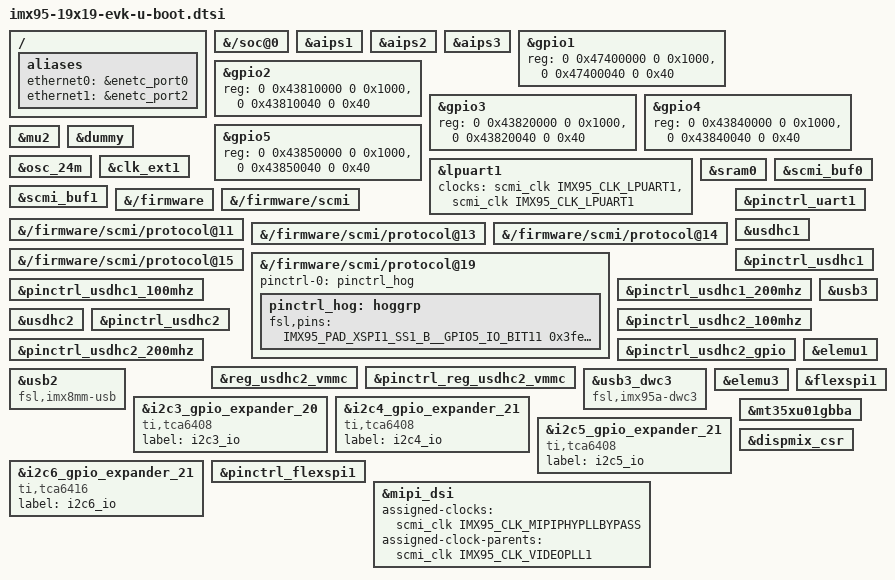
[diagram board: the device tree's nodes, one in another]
// SPDX-License-Identifier: GPL-2.0+
/*
 * Copyright 2023 NXP
 */

/ {
	aliases {
		ethernet0 = &enetc_port0;
		ethernet1 = &enetc_port2;
	};
};

&{/soc@0} {
	bootph-all;
	bootph-pre-ram;
};

&aips1 {
	bootph-all;
	bootph-pre-ram;
};

&aips2 {
	bootph-all;
	bootph-pre-ram;
};

&aips3 {
	bootph-pre-ram;
};

&gpio1 {
	reg = <0 0x47400000 0 0x1000>, <0 0x47400040 0 0x40>;
};

&gpio2 {
	reg = <0 0x43810000 0 0x1000>, <0 0x43810040 0 0x40>;
	bootph-pre-ram;
};

&gpio3 {
	reg = <0 0x43820000 0 0x1000>, <0 0x43820040 0 0x40>;
	bootph-pre-ram;
};

&gpio4 {
	reg = <0 0x43840000 0 0x1000>, <0 0x43840040 0 0x40>;
	bootph-pre-ram;
};

&gpio5 {
	reg = <0 0x43850000 0 0x1000>, <0 0x43850040 0 0x40>;
	bootph-pre-ram;
};

&lpuart1 {
	clocks = <&scmi_clk IMX95_CLK_LPUART1>, <&scmi_clk IMX95_CLK_LPUART1>;
	clock-names = "ipg", "per";
	bootph-pre-ram;
};

&mu2 {
	bootph-all;
	bootph-pre-ram;
};

&dummy {
	bootph-all;
	bootph-pre-ram;
};

&osc_24m {
	bootph-all;
	bootph-pre-ram;
};

&clk_ext1 {
	bootph-all;
	bootph-pre-ram;
};

&sram0 {
	bootph-all;
	bootph-pre-ram;
};

&scmi_buf0 {
	bootph-all;
	bootph-pre-ram;
};

&scmi_buf1 {
	bootph-all;
	bootph-pre-ram;
};

&{/firmware} {
	bootph-all;
        bootph-pre-ram;
};

&{/firmware/scmi} {
	bootph-all;
        bootph-pre-ram;
};

&{/firmware/scmi/protocol@11} {
	bootph-all;
        bootph-pre-ram;
};

&{/firmware/scmi/protocol@13} {
	bootph-all;
        bootph-pre-ram;
};

&{/firmware/scmi/protocol@14} {
	bootph-all;
        bootph-pre-ram;
};

&{/firmware/scmi/protocol@15} {
	bootph-all;
};

&{/firmware/scmi/protocol@19} {
	bootph-all;
	bootph-pre-ram;

	pinctrl-names = "default";
	pinctrl-0 = <&pinctrl_hog>;

	pinctrl_hog: hoggrp {
		bootph-pre-ram;

		fsl,pins = <
			IMX95_PAD_XSPI1_SS1_B__GPIO5_IO_BIT11			0x3fe
			IMX95_PAD_GPIO_IO12__TPM3_CH2           0x51e
			IMX95_PAD_CCM_CLKO1__GPIO3_IO_BIT26			0x3fe
			IMX95_PAD_CCM_CLKO2__GPIO3_IO_BIT27			0x3fe
		>;
	};
};

&pinctrl_uart1 {
	bootph-pre-ram;
};

&usdhc1 {
	bootph-pre-ram;
};

&pinctrl_usdhc1 {
	bootph-pre-ram;
};

&pinctrl_usdhc1_100mhz {
	bootph-pre-ram;
};

&pinctrl_usdhc1_200mhz {
	bootph-pre-ram;
};

&usdhc2 {
	bootph-pre-ram;
};

&pinctrl_usdhc2 {
	bootph-pre-ram;
};

&pinctrl_usdhc2_100mhz {
	bootph-pre-ram;
};

&pinctrl_usdhc2_200mhz {
	bootph-pre-ram;
};

&pinctrl_usdhc2_gpio {
	bootph-pre-ram;
};

&reg_usdhc2_vmmc {
	bootph-pre-ram;
};

&pinctrl_reg_usdhc2_vmmc {
	bootph-pre-ram;
};

&usb2 {
	compatible = "fsl,imx8mm-usb", "fsl,imx7d-usb";
	/delete-property/power-domains;
};

&usb3 {
	/delete-property/power-domains;
};

&usb3_dwc3 {
	compatible = "fsl,imx95a-dwc3", "fsl,imx8mq-dwc3", "snps,dwc3";
};

&elemu1 {
	status = "okay";
	bootph-all;
	bootph-pre-ram;
};

&elemu3 {
	status = "okay";
	bootph-all;
	bootph-pre-ram;
};

&i2c3_gpio_expander_20 {
	compatible = "ti,tca6408";
	label = "i2c3_io";
};

&i2c4_gpio_expander_21 {
	compatible = "ti,tca6408";
	label = "i2c4_io";
};

&i2c5_gpio_expander_21 {
	compatible = "ti,tca6408";
	label = "i2c5_io";
};

&i2c6_gpio_expander_21 {
	compatible = "ti,tca6416";
	label = "i2c6_io";
};

&flexspi1 {
	bootph-pre-ram;
};

&mt35xu01gbba {
	bootph-pre-ram;
};

&pinctrl_flexspi1 {
	bootph-pre-ram;
};

&dispmix_csr {
	/delete-property/ assigned-clocks;
	/delete-property/ assigned-clock-rates;
	/delete-property/ assigned-clock-parents;
};

&mipi_dsi {
	assigned-clocks = <&scmi_clk IMX95_CLK_MIPIPHYPLLBYPASS>;
	assigned-clock-parents = <&scmi_clk IMX95_CLK_VIDEOPLL1>;
};
